# ATSAMB11G18A register map
Vendor: Atmel Corp; Series: SAMB11; File version: TODO
CPU: CM0 r0p0, little endian, no MPU, no FPU, 2 interrupt priority bits
Address unit: 32 bits
Registers are 32-bit, read-write, reset 0x0 unless marked. A register's access mark holds for its fields unless they carry their own. Offsets are from the block's base; [hi:lo] are bit positions; {n}, {i} and the like mark numbered series; 'fields as' and 'values as' point back to an identical list.

## LPMCU_MISC_REGS0 — LPMCU Misc Registers
Base 0x4000B000
0x00 LPMCU_CHIP_ID ro reset 0x2000B0 — The hard-coded ID for the chip.
  [23:0] REV_ID — Chip ID
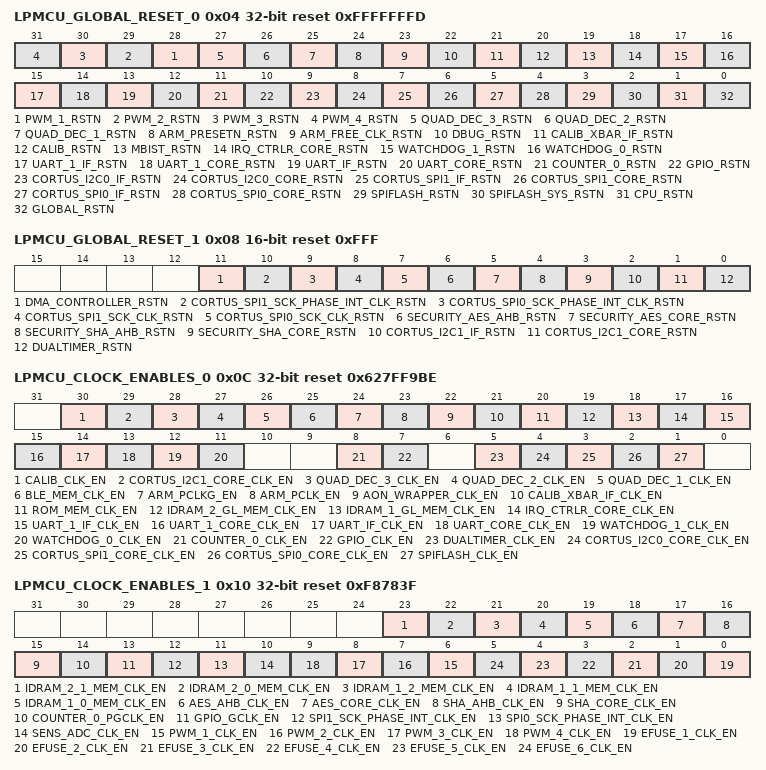
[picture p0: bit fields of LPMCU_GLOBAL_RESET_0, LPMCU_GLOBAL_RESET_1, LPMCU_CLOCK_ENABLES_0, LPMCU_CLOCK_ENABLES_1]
0x04 LPMCU_GLOBAL_RESET_0 reset 0xFFFFFFFD — All individual software controllable resets. 0: Reset the selected function. 1: Normal operation.
  [n+27] PWM_{n}_RSTN (n=1..4) — PWM{n-1} Reset
  [27] QUAD_DEC_3_RSTN — QUAD_DEC2 Reset
  [26] QUAD_DEC_2_RSTN — QUAD_DEC1 Reset
  [25] QUAD_DEC_1_RSTN — QUAD_DEC0 Reset
  [24] ARM_PRESETN_RSTN — ARM APB Reset
  [23] ARM_FREE_CLK_RSTN — Free Running ARM Clock Reset
  [22] DBUG_RSTN — LPMCU Debug Reset
  [21] CALIB_XBAR_IF_RSTN — Low Power Clock Calibration APB Reset
  [20] CALIB_RSTN — Low Power Clock Calibration Core Reset
  [19] MBIST_RSTN — MBIST Logic Reset
  [18] IRQ_CTRLR_CORE_RSTN — NVIC Reset
  [17] WATCHDOG_1_RSTN — WDT1 Reset
  [16] WATCHDOG_0_RSTN — WDT0 Reset
  [15] UART_1_IF_RSTN — UART1 Interface Reset
  [14] UART_1_CORE_RSTN — UART1 Core Reset
  [13] UART_IF_RSTN — UART0 Interface Reset
  [12] UART_CORE_RSTN — UART0 Core Reset
  [11] COUNTER_0_RSTN — TIMER0 Reset
  [10] GPIO_RSTN — GPIO Controller Reset
  [9] CORTUS_I2C0_IF_RSTN — I2C0 Interface Reset
  [8] CORTUS_I2C0_CORE_RSTN — I2C0 Core Reset
  [7] CORTUS_SPI1_IF_RSTN — SPI1 Interface Reset
  [6] CORTUS_SPI1_CORE_RSTN — SPI1 Core Reset
  [5] CORTUS_SPI0_IF_RSTN — SPI0 Interface Reset
  [4] CORTUS_SPI0_CORE_RSTN — SPI0 Core Reset
  [3] SPIFLASH_RSTN — SPI_FLASH0 Interface Reset
  [2] SPIFLASH_SYS_RSTN — SPI_FLASH0 Sys Reset
  [1] CPU_RSTN — LPMCU CPU Reset
  [0] GLOBAL_RSTN — LPMCU Global Reset (self setting)
0x08 LPMCU_GLOBAL_RESET_1 16-bit reset 0xFFF — All individual software controllable resets. 0: Reset the selected function. 1: Normal operation.
  [11] DMA_CONTROLLER_RSTN — PROV_DMA_CTRL0 Reset
  [10] CORTUS_SPI1_SCK_PHASE_INT_CLK_RSTN — SPI1 SCK Phase Clock Reset
  [9] CORTUS_SPI0_SCK_PHASE_INT_CLK_RSTN — SPI0 SCK Phase Clock Reset
  [8] CORTUS_SPI1_SCK_CLK_RSTN — SPI1 SCK Clock Reset
  [7] CORTUS_SPI0_SCK_CLK_RSTN — SPI0 SCK Clock Reset
  [6] SECURITY_AES_AHB_RSTN — Security AES AHB Interface Reset
  [5] SECURITY_AES_CORE_RSTN — Security AES Core Reset
  [4] SECURITY_SHA_AHB_RSTN — Security SHA AHB Interface Reset
  [3] SECURITY_SHA_CORE_RSTN — Security SHA Core Reset
  [2] CORTUS_I2C1_IF_RSTN — I2C1 Interface Reset
  [1] CORTUS_I2C1_CORE_RSTN — I2C1 Core Reset
  [0] DUALTIMER_RSTN — DUALTIMER0 Reset
0x0C LPMCU_CLOCK_ENABLES_0 reset 0x627FF9BE — All individual software controllable clock enables. Values are: 0: Disable clock. 1: Normal operation.
  [30] CALIB_CLK_EN — Low Power Clock Calibration Core Clock Enable
  [29] CORTUS_I2C1_CORE_CLK_EN — I2C1 Core Clock Enable
  [28] QUAD_DEC_3_CLK_EN — QUAD_DEC2 Clock Enable
  [27] QUAD_DEC_2_CLK_EN — QUAD_DEC1 Clock Enable
  [26] QUAD_DEC_1_CLK_EN — QUAD_DEC0 Clock Enable
  [25] BLE_MEM_CLK_EN — ARM BLE 8K Retention Memory Clock Enable
  [24] ARM_PCLKG_EN — ARM Gated PCLK Clock Enable (override)
  [23] ARM_PCLK_EN — ARM PCLK Clock Enable (override)
  [22] AON_WRAPPER_CLK_EN — AON Wrapper Clock Enable
  [21] CALIB_XBAR_IF_CLK_EN — Low Power Clock Calibration Interface Clock Enable
  [20] ROM_MEM_CLK_EN — ROM Clock Enable
  [19] IDRAM_2_GL_MEM_CLK_EN — IDRAM2 Glue Logic Clock Enable
  [18] IDRAM_1_GL_MEM_CLK_EN — IDRAM1 Glue Logic Clock Enable
  [17] IRQ_CTRLR_CORE_CLK_EN — NVIC Clock Enable
  [16] UART_1_IF_CLK_EN — UART1 Interface Clock Enable
  [15] UART_1_CORE_CLK_EN — UART1 Core Clock Enable
  [14] UART_IF_CLK_EN — UART0 Interface Clock Enable
  [13] UART_CORE_CLK_EN — UART0 Core Clock Enable
  [12] WATCHDOG_1_CLK_EN — WDT1 Clock Enable
  [11] WATCHDOG_0_CLK_EN — WDT0 Clock Enable
  [8] COUNTER_0_CLK_EN — TIMER0 Clock Enable
  [7] GPIO_CLK_EN — GPIO Controller Clock Enable
  [5] DUALTIMER_CLK_EN — DUALTIMER0 Clock Enable
  [4] CORTUS_I2C0_CORE_CLK_EN — I2C0 Core Clock Enable
  [3] CORTUS_SPI1_CORE_CLK_EN — SPI1 Core Clock Enable
  [2] CORTUS_SPI0_CORE_CLK_EN — SPI0 Core Clock Enable
  [1] SPIFLASH_CLK_EN — SPI_FLASH0 Clock Enable
0x10 LPMCU_CLOCK_ENABLES_1 reset 0xF8783F — All individual software controllable clock enables. Values are: 0: Disable clock. 1: Normal operation.
  [23] IDRAM_2_1_MEM_CLK_EN — IDRAM2_1 Memory Clock Enable
  [22] IDRAM_2_0_MEM_CLK_EN — IDRAM2_0 Memory Clock Enable
  [21] IDRAM_1_2_MEM_CLK_EN — IDRAM1_2 Memory Clock Enable
  [20] IDRAM_1_1_MEM_CLK_EN — IDRAM1_1 Memory Clock Enable
  [19] IDRAM_1_0_MEM_CLK_EN — IDRAM1_0 Memory Clock Enable
  [18] AES_AHB_CLK_EN — AES AHB Clock Enable
  [17] AES_CORE_CLK_EN — AES Core Clock Enable
  [16] SHA_AHB_CLK_EN — SHA AHB Clock Enable
  [15] SHA_CORE_CLK_EN — SHA Core Clock Enable
  [14] COUNTER_0_PGCLK_EN — TIMER0 Gated APB Clock
  [13] GPIO_GCLK_EN — GPIO Controller Clock Enable
  [12] SPI1_SCK_PHASE_INT_CLK_EN — SPI1 SCK Phase Internal Clock Enable
  [11] SPI0_SCK_PHASE_INT_CLK_EN — SPI0 SCK Phase Internal Clock Enable
  [10] SENS_ADC_CLK_EN — PMU Sensor ADC Clock Enable
  [n+5] PWM_{n}_CLK_EN (n=1..4) — PWM{n-1} Clock Enable
  [n-1] EFUSE_{n}_CLK_EN (n=1..6) — EFUSE{n-1} Clock Enable
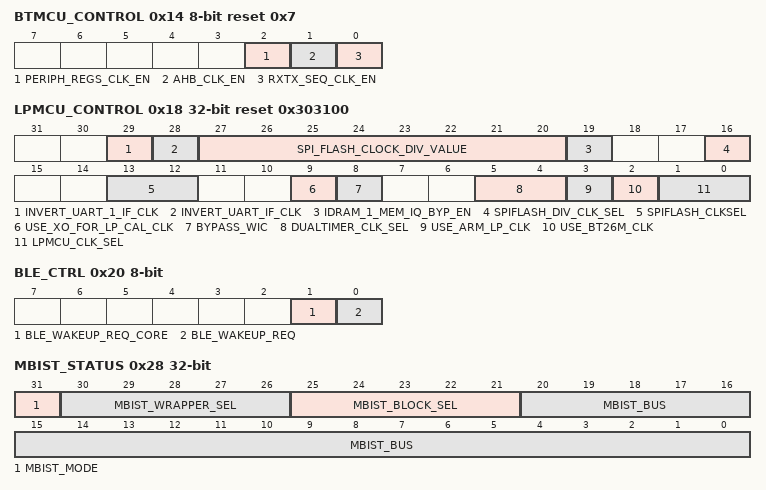
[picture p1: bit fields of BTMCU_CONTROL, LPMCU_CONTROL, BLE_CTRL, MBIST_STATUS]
0x14 BTMCU_CONTROL 8-bit reset 0x7 — Miscellaneous BLE control
  [2] PERIPH_REGS_CLK_EN — BLE Periph Regs Clock Enable
  [1] AHB_CLK_EN — BLE HAB Clock Enable
  [0] RXTX_SEQ_CLK_EN — BLE RXTX Sequencer Clock Enable
0x18 LPMCU_CONTROL reset 0x303100 — Miscellaneous LPMCU control
  [29] INVERT_UART_1_IF_CLK — Inverts UART1 interface clock
  [28] INVERT_UART_IF_CLK — Inverts UART0 interface clock
  [27:20] SPI_FLASH_CLOCK_DIV_VALUE — Integer divider value. 26mhz clock will be divided by this register value
  [19] IDRAM_1_MEM_IQ_BYP_EN — Mux Control to select between FECE and standard IDRAM memory. Default to IDRAM ARM Memory
  [16] SPIFLASH_DIV_CLK_SEL — Use Generated Divided Clock for SPI_FLASH0
  [13:12] SPIFLASH_CLKSEL — SPI_FLASH0 Clock Frequency Select
    0=3.25MHz; 1=6.5MHz; 2=13MHz; 3=26MHz
  [9] USE_XO_FOR_LP_CAL_CLK — Use the XO for Low Power Clock Calibration
  [8] BYPASS_WIC — Bypass Wakeup Interrupt Controller
  [5:4] DUALTIMER_CLK_SEL — DUALTIMER0 Clock Frequency Select
    0=26MHz; 1=13MHz; 2=6.5MHz; 3=3.25MHz
  [3] USE_ARM_LP_CLK — Use either LP 2MHz clock or XO as ARM clock
  [2] USE_BT26M_CLK — Use XO as ARM clock (must also set use_arm_lp_clk)
  [1:0] LPMCU_CLK_SEL — LPMCU Clock Frequency Selection
    0=26MHz; 1=13MHz; 2=6.5MHz; 3=3.25MHz
0x1C LPMCU_MBIST 8-bit — MBIST designation
  [0] MBIST_MODE — Puts the chip in MBIST mode
0x20 BLE_CTRL 8-bit — BLE Control
  [1] BLE_WAKEUP_REQ_CORE — BLE Wakeup Request (to BLE Core)
  [0] BLE_WAKEUP_REQ — BLE Wakeup Request (to BLE Sleep Timer)
0x24 MBIST_CONTROL (reset mask 0x7FFFF)
0x28 MBIST_STATUS ro
  [31] MBIST_MODE — Observation of mbist_mode signal
  [30:26] MBIST_WRAPPER_SEL — Observation of wrapper field of MBIST control
  [25:21] MBIST_BLOCK_SEL — Observation of block field of MBIST control
  [20:0] MBIST_BUS — Observation of MBIST results
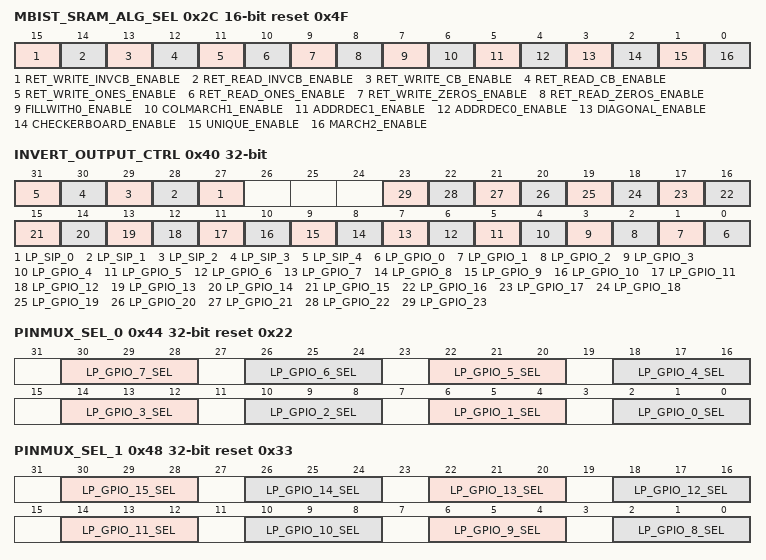
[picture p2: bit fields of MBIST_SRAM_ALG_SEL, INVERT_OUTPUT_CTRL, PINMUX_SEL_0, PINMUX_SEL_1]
0x2C MBIST_SRAM_ALG_SEL 16-bit reset 0x4F — Enables MBIST algorithms
  [15] RET_WRITE_INVCB_ENABLE — Enables the ret write inv checkerboard algorithm
  [14] RET_READ_INVCB_ENABLE — Enables the ret read inv checkerboard algorithm
  [13] RET_WRITE_CB_ENABLE — Enables the ret write checkerboard algorithm
  [12] RET_READ_CB_ENABLE — Enables the ret read checkerboard algorithm
  [11] RET_WRITE_ONES_ENABLE — Enables the ret write ones algorithm
  [10] RET_READ_ONES_ENABLE — Enables the ret read ones algorithm
  [9] RET_WRITE_ZEROS_ENABLE — Enables the ret write zeros algorithm
  [8] RET_READ_ZEROS_ENABLE — Enables the ret read zeros algorithm
  [7] FILLWITH0_ENABLE — Enables the fillwith0 algorithm
  [6] COLMARCH1_ENABLE — Enables the col_march1 algorithm
  [5] ADDRDEC1_ENABLE — Enables the address decoder bg1 algorithm
  [4] ADDRDEC0_ENABLE — Enables the address decoder bg0 algorithm
  [3] DIAGONAL_ENABLE — Enables the diagonal algorithm
  [2] CHECKERBOARD_ENABLE — Enables the checkerboard algorithm
  [1] UNIQUE_ENABLE — Enables the unique address algorithm
  [0] MARCH2_ENABLE — Enables the march2 algorithm
0x30 MBIST_BG — MBIST Background for MARCH2 algorithm (bits 31:0)
0x38 TEST_BUS_CONTROL 8-bit — Controls all of the test bus functionality
  [0] TEST_ENABLE_ARM — Selects periph test bus
0x3C WP3_MISR_DATAOUT ro — ROM MBIST Signature
0x40 INVERT_OUTPUT_CTRL — Invert Output Control
  [n+27] LP_SIP_{n} (n=0..4) — Invert the output for lp_sip_{n}
  [n] LP_GPIO_{n} (n=0..23) — Invert the output for lp_gpio_{n}
0x44 PINMUX_SEL_0 reset 0x22 — Pinmux select for LP_GPIO_0, LP_GPIO_1, LP_GPIO_2, LP_GPIO_3, LP_GPIO_4, LP_GPIO_5, LP_GPIO_6, LP_GPIO_7
  [30:28] LP_GPIO_7_SEL — Pinmux select for LP_GPIO_7
    0=GPIO (MUX function 0); 1=MEGAMUX (MUX function 1); 2=UART1_TXD (MUX function 2); 5=SPI0_MOSI (MUX function 5); 6=SPI_FLASH0_TXD (MUX function 6); 7=TEST_OUT_7 (MUX function 7)
  [26:24] LP_GPIO_6_SEL — Pinmux select for LP_GPIO_6
    0=GPIO (MUX function 0); 1=MEGAMUX (MUX function 1); 2=UART1_RXD (MUX function 2); 5=SPI0_SCK (MUX function 5); 6=SPI_FLASH0_SCK (MUX function 6); 7=TEST_OUT_6 (MUX function 7)
  [22:20] LP_GPIO_5_SEL — Pinmux select for LP_GPIO_5
    0=GPIO (MUX function 0); 1=MEGAMUX (MUX function 1); 2=UART0_RTS (MUX function 2); 4=SPI1_MISO (MUX function 4); 5=SPI0_MISO (MUX function 5); 6=SPI_FLASH0_RXD (MUX function 6); 7=TEST_OUT_5 (MUX function 7)
  [18:16] LP_GPIO_4_SEL — Pinmux select for LP_GPIO_4
    0=GPIO (MUX function 0); 1=MEGAMUX (MUX function 1); 2=UART0_CTS (MUX function 2); 4=SPI1_SSN (MUX function 4); 5=SPI0_SSN (MUX function 5); 6=SPI_FLASH0_SSN (MUX function 6); 7=TEST_OUT_4 (MUX function 7)
  [14:12] LP_GPIO_3_SEL — Pinmux select for LP_GPIO_3
    0=GPIO (MUX function 0); 1=MEGAMUX (MUX function 1); 2=UART0_TXD (MUX function 2); 4=SPI1_MOSI (MUX function 4); 5=SPI0_MOSI (MUX function 5); 6=SPI_FLASH0_TXD (MUX function 6); 7=TEST_OUT_3 (MUX function 7)
  [10:8] LP_GPIO_2_SEL — Pinmux select for LP_GPIO_2
    0=GPIO (MUX function 0); 1=MEGAMUX (MUX function 1); 2=UART0_RXD (MUX function 2); 4=SPI1_SCK (MUX function 4); 5=SPI0_SCK (MUX function 5); 6=SPI_FLASH0_SCK (MUX function 6); 7=TEST_OUT_2 (MUX function 7)
  [6:4] LP_GPIO_1_SEL — Pinmux select for LP_GPIO_1
    0=GPIO (MUX function 0); 1=MEGAMUX (MUX function 1); 2=SWD_IO (MUX function 2); 7=TEST_OUT_1 (MUX function 7)
  [2:0] LP_GPIO_0_SEL — Pinmux select for LP_GPIO_0
    0=GPIO (MUX function 0); 1=MEGAMUX (MUX function 1); 2=SWD_CLK (MUX function 2); 7=TEST_OUT_0 (MUX function 7)
0x48 PINMUX_SEL_1 reset 0x33 — Pinmux select for LP_GPIO_8, LP_GPIO_9, LP_GPIO_10, LP_GPIO_11, LP_GPIO_12, LP_GPIO_13, LP_GPIO_14, LP_GPIO_15
  [30:28] LP_GPIO_15_SEL — Pinmux select for LP_GPIO_15
    0=GPIO (MUX function 0); 1=MEGAMUX (MUX function 1); 2=UART1_RTS (MUX function 2); 4=I2C1_SCL (MUX function 4); 7=TEST_OUT_15 (MUX function 7)
  [26:24] LP_GPIO_14_SEL — Pinmux select for LP_GPIO_14
    0=GPIO (MUX function 0); 1=MEGAMUX (MUX function 1); 2=UART1_CTS (MUX function 2); 4=I2C1_SDA (MUX function 4); 7=TEST_OUT_14 (MUX function 7)
  [22:20] LP_GPIO_13_SEL — Pinmux select for LP_GPIO_13
    0=GPIO (MUX function 0); 1=MEGAMUX (MUX function 1); 2=SPI0_MISO (MUX function 2); 6=SPI_FLASH0_RXD (MUX function 6); 7=TEST_OUT_13 (MUX function 7)
  [18:16] LP_GPIO_12_SEL — Pinmux select for LP_GPIO_12
    0=GPIO (MUX function 0); 1=MEGAMUX (MUX function 1); 2=SPI0_SSN (MUX function 2); 6=SPI_FLASH0_SSN (MUX function 6); 7=TEST_OUT_12 (MUX function 7)
  [14:12] LP_GPIO_11_SEL — Pinmux select for LP_GPIO_11
    0=GPIO (MUX function 0); 1=MEGAMUX (MUX function 1); 2=SPI0_MOSI (MUX function 2); 6=SPI_FLASH0_TXD (MUX function 6); 7=TEST_OUT_11 (MUX function 7)
  [10:8] LP_GPIO_10_SEL — Pinmux select for LP_GPIO_10
    0=GPIO (MUX function 0); 1=MEGAMUX (MUX function 1); 2=SPI0_SCK (MUX function 2); 6=SPI_FLASH0_SCK (MUX function 6); 7=TEST_OUT_10 (MUX function 7)
  [6:4] LP_GPIO_9_SEL — Pinmux select for LP_GPIO_9
    0=GPIO (MUX function 0); 1=MEGAMUX (MUX function 1); 2=I2C0_SCL (MUX function 2); 5=SPI0_MISO (MUX function 5); 6=SPI_FLASH0_RXD (MUX function 6); 7=TEST_OUT_9 (MUX function 7)
  [2:0] LP_GPIO_8_SEL — Pinmux select for LP_GPIO_8
    0=GPIO (MUX function 0); 1=MEGAMUX (MUX function 1); 2=I2C0_SDA (MUX function 2); 5=SPI0_SSN (MUX function 5); 6=SPI_FLASH0_SSN (MUX function 6); 7=TEST_OUT_8 (MUX function 7)
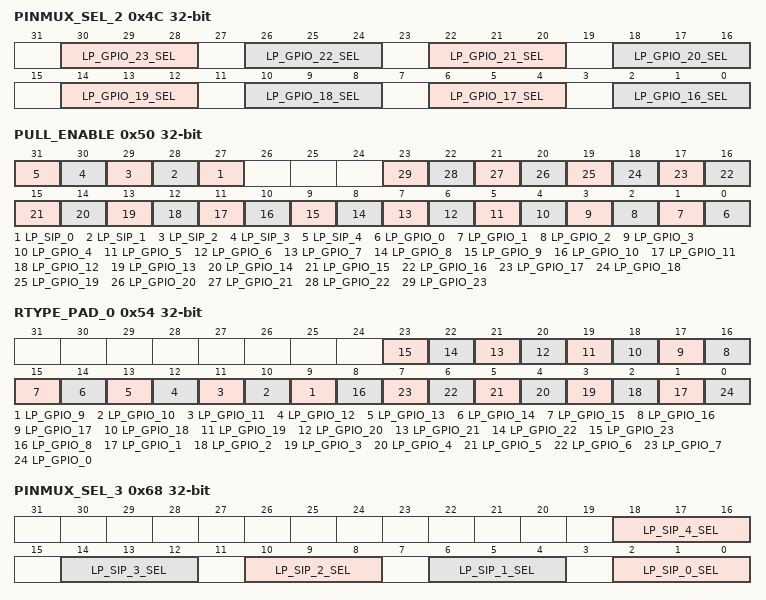
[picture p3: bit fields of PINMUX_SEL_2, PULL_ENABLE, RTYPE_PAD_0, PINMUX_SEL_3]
0x4C PINMUX_SEL_2 — Pinmux select for LP_GPIO_16, LP_GPIO_17, LP_GPIO_18, LP_GPIO_19, LP_GPIO_20, LP_GPIO_21, LP_GPIO_22, LP_GPIO_23
  [30:28] LP_GPIO_23_SEL — Pinmux select for LP_GPIO_23
    0=GPIO (MUX function 0); 1=MEGAMUX (MUX function 1)
  [26:24] LP_GPIO_22_SEL — Pinmux select for LP_GPIO_22
    0=GPIO (MUX function 0); 1=MEGAMUX (MUX function 1)
  [22:20] LP_GPIO_21_SEL — Pinmux select for LP_GPIO_21
    0=GPIO (MUX function 0); 1=MEGAMUX (MUX function 1)
  [18:16] LP_GPIO_20_SEL — Pinmux select for LP_GPIO_20
    0=GPIO (MUX function 0); 1=MEGAMUX (MUX function 1); 7=TEST_OUT_20 (MUX function 7)
  [14:12] LP_GPIO_19_SEL — Pinmux select for LP_GPIO_19
    0=GPIO (MUX function 0); 1=MEGAMUX (MUX function 1); 2=SPI_FLASH0_RXD (MUX function 2); 4=SPI1_MOSI (MUX function 4); 5=SPI0_MISO (MUX function 5); 7=TEST_OUT_19 (MUX function 7)
  [10:8] LP_GPIO_18_SEL — Pinmux select for LP_GPIO_18
    0=GPIO (MUX function 0); 1=MEGAMUX (MUX function 1); 2=SPI_FLASH0_SSN (MUX function 2); 4=SPI1_MISO (MUX function 4); 5=SPI0_SSN (MUX function 5); 6=SPI_FLASH0_RXD (MUX function 6); 7=TEST_OUT_18 (MUX function 7)
  [6:4] LP_GPIO_17_SEL — Pinmux select for LP_GPIO_17
    0=GPIO (MUX function 0); 1=MEGAMUX (MUX function 1); 2=SPI_FLASH0_TXD (MUX function 2); 4=SPI1_SCK (MUX function 4); 5=SPI0_MOSI (MUX function 5); 7=TEST_OUT_17 (MUX function 7)
  [2:0] LP_GPIO_16_SEL — Pinmux select for LP_GPIO_16
    0=GPIO (MUX function 0); 1=MEGAMUX (MUX function 1); 2=SPI_FLASH0_SCK (MUX function 2); 4=SPI1_SSN (MUX function 4); 5=SPI0_SCK (MUX function 5); 6=SPI_FLASH0_SSN (MUX function 6); 7=TEST_OUT_16 (MUX function 7)
0x50 PULL_ENABLE — Active Low Pull Enables for LPMCU Pads
  [n+27] LP_SIP_{n} (n=0..4) — Pull Enable for LP_SIP_{n}
  [n] LP_GPIO_{n} (n=0..23) — Pull Enable for LP_GPIO_{n}
0x54 RTYPE_PAD_0 — Controls the RTYPE (Pull Level) pad value for LPMCU Pads (0 = Pull Up)
  [n] LP_GPIO_{n} (n=9..23) — Controls RTYPE (Pull Level) value LP_GPIO_{n}
  [8] LP_GPIO_8 — Controls RTYPE (Pull Level) value for LP_GPIO_8
  [n] LP_GPIO_{n} (n=1..7) — Controls RTYPE (Pull Level) value LP_GPIO_{n}
  [0] LP_GPIO_0 — Controls RTYPE (Pull Level) value for LP_GPIO_0
0x68 PINMUX_SEL_3 — Pinmux select for LP_SIP_0, LP_SIP_1, LP_SIP_2, LP_SIP_3, LP_SIP_4
  [18:16] LP_SIP_4_SEL — Pinmux select for LP_SIP_4
    0=SPI_FLASH0_WP (MUX function 0)
  [14:12] LP_SIP_3_SEL — Pinmux select for LP_SIP_3
    4=SPI_FLASH0_RXD (MUX function 4)
  [10:8] LP_SIP_2_SEL — Pinmux select for LP_SIP_2
    2=SPI_FLASH0_SSN (MUX function 2)
  [6:4] LP_SIP_1_SEL — Pinmux select for LP_SIP_1
    3=SPI_FLASH0_TXD (MUX function 3)
  [2:0] LP_SIP_0_SEL — Pinmux select for LP_SIP_0
    1=SPI_FLASH0_SCK (MUX function 1)
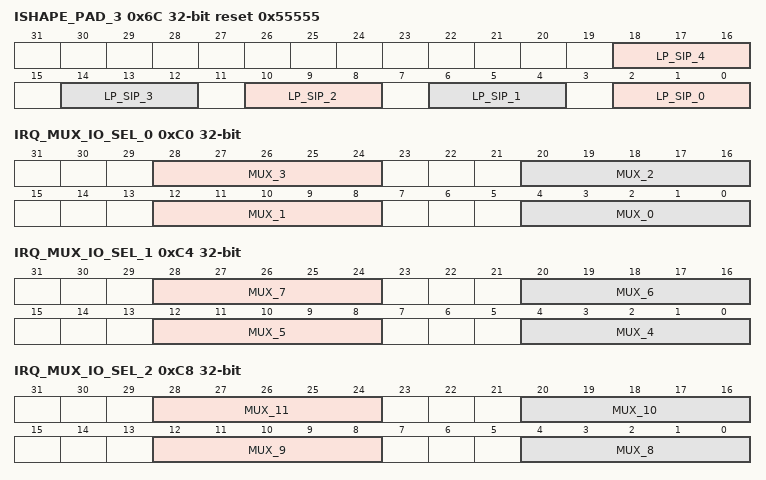
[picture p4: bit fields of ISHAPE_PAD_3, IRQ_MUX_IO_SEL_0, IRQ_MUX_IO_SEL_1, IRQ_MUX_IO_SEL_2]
0x6C ISHAPE_PAD_3 reset 0x55555 — Controls the ISHAPE pad value for LPMCU SIP Pads
  [4n+2:4n] LP_SIP_{n} (n=0..4) — Controls ISHAPE value LP_SIP_{n}
0x80 PINMUX_SEL_4 8-bit — Pinmux select for LP_GPIO_24
  [2:0] LP_GPIO_24_SEL
    0=GPIO (MUX function 0); 1=MEGAMUX (MUX function 1)
0x90 LPMCU_CONTROL_2 8-bit — Misc control for the LPMCU
  [7:0] SPI_FLASH_CLOCK_FRAC_VALUE — SPI_FLASH0 Fractional Divider Value
0xA0 SPIFLASH_VDDIO_CTRL 8-bit reset 0x1 — Control for VDDIO of SPI FLASH
  [0] ENABLE — Enables power for the stacked (internal) SPI FLASH
0xA4 SPIFLASH_BYPASS 8-bit
  [0] ENABLE — Enables Bypass of SPI Flash Controller
0xC0 IRQ_MUX_IO_SEL_0 — Arm Cortex IRQ Mux Selection (Refer to Interrupts Spreadsheet)
  [28:24] MUX_3 — IRQ_3 Source Selection
    0=UART1 TX; 1=UART0 RX; 2=UART0 TX; 3=UART1 RX; 4=UART1 TX; 5=SPI0 RX; 6=SPI0 TX; 7=SPI1 RX; 8=SPI1 TX; 9=I2C0 RX; 10=I2C0 TX; 11=I2C1 RX; 12=I2C1 TX; 13=WDT0; 14=WDT1; 15=DUALTIMER0; 16=PROV_DMA_CTRL0; 17=SECURITY; 18=EFUSE_OUT_OF_RESET; 19=QUAD_DEC0_1_2; 20=BLE_FRONTEND; 21=PROG_AHB_TRIG_TIMEOUT; 22=SXPLL_NEED_RESET; 23=LP_CLK_CAL_DONE; 24=BROWNOUT_DETECTED
  [20:16] MUX_2 — IRQ_2 Source Selection
    0=UART1 RX; 1=UART0 RX; 2=UART0 TX; 3=UART1 RX; 4=UART1 TX; 5=SPI0 RX; 6=SPI0 TX; 7=SPI1 RX; 8=SPI1 TX; 9=I2C0 RX; 10=I2C0 TX; 11=I2C1 RX; 12=I2C1 TX; 13=WDT0; 14=WDT1; 15=DUALTIMER0; 16=PROV_DMA_CTRL0; 17=SECURITY; 18=EFUSE_OUT_OF_RESET; 19=QUAD_DEC0_1_2; 20=BLE_FRONTEND; 21=PROG_AHB_TRIG_TIMEOUT; 22=SXPLL_NEED_RESET; 23=LP_CLK_CAL_DONE; 24=BROWNOUT_DETECTED
  [12:8] MUX_1 — IRQ_1 Source Selection
    0=UART0 TX; 1=UART0 RX; 2=UART0 TX; 3=UART1 RX; 4=UART1 TX; 5=SPI0 RX; 6=SPI0 TX; 7=SPI1 RX; 8=SPI1 TX; 9=I2C0 RX; 10=I2C0 TX; 11=I2C1 RX; 12=I2C1 TX; 13=WDT0; 14=WDT1; 15=DUALTIMER0; 16=PROV_DMA_CTRL0; 17=SECURITY; 18=EFUSE_OUT_OF_RESET; 19=QUAD_DEC0_1_2; 20=BLE_FRONTEND; 21=PROG_AHB_TRIG_TIMEOUT; 22=SXPLL_NEED_RESET; 23=LP_CLK_CAL_DONE; 24=BROWNOUT_DETECTED
  [4:0] MUX_0 — IRQ_0 Source Selection
    0=UART0 RX; 1=UART0 RX; 2=UART0 TX; 3=UART1 RX; 4=UART1 TX; 5=SPI0 RX; 6=SPI0 TX; 7=SPI1 RX; 8=SPI1 TX; 9=I2C0 RX; 10=I2C0 TX; 11=I2C1 RX; 12=I2C1 TX; 13=WDT0; 14=WDT1; 15=DUALTIMER0; 16=PROV_DMA_CTRL0; 17=SECURITY; 18=EFUSE_OUT_OF_RESET; 19=QUAD_DEC0_1_2; 20=BLE_FRONTEND; 21=PROG_AHB_TRIG_TIMEOUT; 22=SXPLL_NEED_RESET; 23=LP_CLK_CAL_DONE; 24=BROWNOUT_DETECTED
0xC4 IRQ_MUX_IO_SEL_1 — Arm Cortex IRQ Mux Selection (Refer to Interrupts Spreadsheet)
  [28:24] MUX_7 — IRQ_7 Source Selection
    0=SPI1 TX; 1=UART0 RX; 2=UART0 TX; 3=UART1 RX; 4=UART1 TX; 5=SPI0 RX; 6=SPI0 TX; 7=SPI1 RX; 8=SPI1 TX; 9=I2C0 RX; 10=I2C0 TX; 11=I2C1 RX; 12=I2C1 TX; 13=WDT0; 14=WDT1; 15=DUALTIMER0; 16=PROV_DMA_CTRL0; 17=SECURITY; 18=EFUSE_OUT_OF_RESET; 19=QUAD_DEC0_1_2; 20=BLE_FRONTEND; 21=PROG_AHB_TRIG_TIMEOUT; 22=SXPLL_NEED_RESET; 23=LP_CLK_CAL_DONE; 24=BROWNOUT_DETECTED
  [20:16] MUX_6 — IRQ_6 Source Selection
    0=SPI1 RX; 1=UART0 RX; 2=UART0 TX; 3=UART1 RX; 4=UART1 TX; 5=SPI0 RX; 6=SPI0 TX; 7=SPI1 RX; 8=SPI1 TX; 9=I2C0 RX; 10=I2C0 TX; 11=I2C1 RX; 12=I2C1 TX; 13=WDT0; 14=WDT1; 15=DUALTIMER0; 16=PROV_DMA_CTRL0; 17=SECURITY; 18=EFUSE_OUT_OF_RESET; 19=QUAD_DEC0_1_2; 20=BLE_FRONTEND; 21=PROG_AHB_TRIG_TIMEOUT; 22=SXPLL_NEED_RESET; 23=LP_CLK_CAL_DONE; 24=BROWNOUT_DETECTED
  [12:8] MUX_5 — IRQ_5 Source Selection
    0=SPI0 TX; 1=UART0 RX; 2=UART0 TX; 3=UART1 RX; 4=UART1 TX; 5=SPI0 RX; 6=SPI0 TX; 7=SPI1 RX; 8=SPI1 TX; 9=I2C0 RX; 10=I2C0 TX; 11=I2C1 RX; 12=I2C1 TX; 13=WDT0; 14=WDT1; 15=DUALTIMER0; 16=PROV_DMA_CTRL0; 17=SECURITY; 18=EFUSE_OUT_OF_RESET; 19=QUAD_DEC0_1_2; 20=BLE_FRONTEND; 21=PROG_AHB_TRIG_TIMEOUT; 22=SXPLL_NEED_RESET; 23=LP_CLK_CAL_DONE; 24=BROWNOUT_DETECTED
  [4:0] MUX_4 — IRQ_4 Source Selection
    0=SPI0 RX; 1=UART0 RX; 2=UART0 TX; 3=UART1 RX; 4=UART1 TX; 5=SPI0 RX; 6=SPI0 TX; 7=SPI1 RX; 8=SPI1 TX; 9=I2C0 RX; 10=I2C0 TX; 11=I2C1 RX; 12=I2C1 TX; 13=WDT0; 14=WDT1; 15=DUALTIMER0; 16=PROV_DMA_CTRL0; 17=SECURITY; 18=EFUSE_OUT_OF_RESET; 19=QUAD_DEC0_1_2; 20=BLE_FRONTEND; 21=PROG_AHB_TRIG_TIMEOUT; 22=SXPLL_NEED_RESET; 23=LP_CLK_CAL_DONE; 24=BROWNOUT_DETECTED
0xC8 IRQ_MUX_IO_SEL_2 — Arm Cortex IRQ Mux Selection (Refer to Interrupts Spreadsheet)
  [28:24] MUX_11 — IRQ_11 Source Selection
    0=I2C1 TX; 1=UART0 RX; 2=UART0 TX; 3=UART1 RX; 4=UART1 TX; 5=SPI0 RX; 6=SPI0 TX; 7=SPI1 RX; 8=SPI1 TX; 9=I2C0 RX; 10=I2C0 TX; 11=I2C1 RX; 12=I2C1 TX; 13=WDT0; 14=WDT1; 15=DUALTIMER0; 16=PROV_DMA_CTRL0; 17=SECURITY; 18=EFUSE_OUT_OF_RESET; 19=QUAD_DEC0_1_2; 20=BLE_FRONTEND; 21=PROG_AHB_TRIG_TIMEOUT; 22=SXPLL_NEED_RESET; 23=LP_CLK_CAL_DONE; 24=BROWNOUT_DETECTED
  [20:16] MUX_10 — IRQ_10 Source Selection
    0=I2C1 RX; 1=UART0 RX; 2=UART0 TX; 3=UART1 RX; 4=UART1 TX; 5=SPI0 RX; 6=SPI0 TX; 7=SPI1 RX; 8=SPI1 TX; 9=I2C0 RX; 10=I2C0 TX; 11=I2C1 RX; 12=I2C1 TX; 13=WDT0; 14=WDT1; 15=DUALTIMER0; 16=PROV_DMA_CTRL0; 17=SECURITY; 18=EFUSE_OUT_OF_RESET; 19=QUAD_DEC0_1_2; 20=BLE_FRONTEND; 21=PROG_AHB_TRIG_TIMEOUT; 22=SXPLL_NEED_RESET; 23=LP_CLK_CAL_DONE; 24=BROWNOUT_DETECTED
  [12:8] MUX_9 — IRQ_9 Source Selection
    0=I2C0 TX; 1=UART0 RX; 2=UART0 TX; 3=UART1 RX; 4=UART1 TX; 5=SPI0 RX; 6=SPI0 TX; 7=SPI1 RX; 8=SPI1 TX; 9=I2C0 RX; 10=I2C0 TX; 11=I2C1 RX; 12=I2C1 TX; 13=WDT0; 14=WDT1; 15=DUALTIMER0; 16=PROV_DMA_CTRL0; 17=SECURITY; 18=EFUSE_OUT_OF_RESET; 19=QUAD_DEC0_1_2; 20=BLE_FRONTEND; 21=PROG_AHB_TRIG_TIMEOUT; 22=SXPLL_NEED_RESET; 23=LP_CLK_CAL_DONE; 24=BROWNOUT_DETECTED
  [4:0] MUX_8 — IRQ_8 Source Selection
    0=I2C0 RX; 1=UART0 RX; 2=UART0 TX; 3=UART1 RX; 4=UART1 TX; 5=SPI0 RX; 6=SPI0 TX; 7=SPI1 RX; 8=SPI1 TX; 9=I2C0 RX; 10=I2C0 TX; 11=I2C1 RX; 12=I2C1 TX; 13=WDT0; 14=WDT1; 15=DUALTIMER0; 16=PROV_DMA_CTRL0; 17=SECURITY; 18=EFUSE_OUT_OF_RESET; 19=QUAD_DEC0_1_2; 20=BLE_FRONTEND; 21=PROG_AHB_TRIG_TIMEOUT; 22=SXPLL_NEED_RESET; 23=LP_CLK_CAL_DONE; 24=BROWNOUT_DETECTED
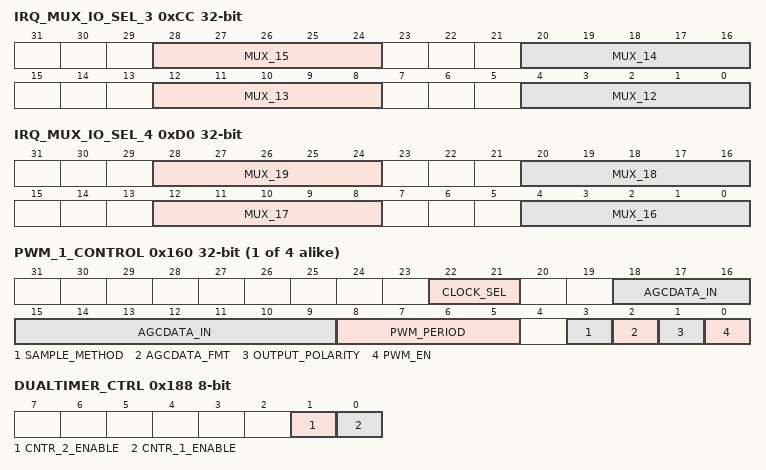
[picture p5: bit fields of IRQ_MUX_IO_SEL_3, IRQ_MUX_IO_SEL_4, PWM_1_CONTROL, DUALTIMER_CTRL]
0xCC IRQ_MUX_IO_SEL_3 — Arm Cortex IRQ Mux Selection (Refer to Interrupts Spreadsheet)
  [28:24] MUX_15 — IRQ_15 Source Selection
    0=PROV_DMA_CTRL0; 1=UART0 RX; 2=UART0 TX; 3=UART1 RX; 4=UART1 TX; 5=SPI0 RX; 6=SPI0 TX; 7=SPI1 RX; 8=SPI1 TX; 9=I2C0 RX; 10=I2C0 TX; 11=I2C1 RX; 12=I2C1 TX; 13=WDT0; 14=WDT1; 15=DUALTIMER0; 16=PROV_DMA_CTRL0; 17=SECURITY; 18=EFUSE_OUT_OF_RESET; 19=QUAD_DEC0_1_2; 20=BLE_FRONTEND; 21=PROG_AHB_TRIG_TIMEOUT; 22=SXPLL_NEED_RESET; 23=LP_CLK_CAL_DONE; 24=BROWNOUT_DETECTED
  [20:16] MUX_14 — IRQ_14 Source Selection
    0=DUALTIMER0; 1=UART0 RX; 2=UART0 TX; 3=UART1 RX; 4=UART1 TX; 5=SPI0 RX; 6=SPI0 TX; 7=SPI1 RX; 8=SPI1 TX; 9=I2C0 RX; 10=I2C0 TX; 11=I2C1 RX; 12=I2C1 TX; 13=WDT0; 14=WDT1; 15=DUALTIMER0; 16=PROV_DMA_CTRL0; 17=SECURITY; 18=EFUSE_OUT_OF_RESET; 19=QUAD_DEC0_1_2; 20=BLE_FRONTEND; 21=PROG_AHB_TRIG_TIMEOUT; 22=SXPLL_NEED_RESET; 23=LP_CLK_CAL_DONE; 24=BROWNOUT_DETECTED
  [12:8] MUX_13 — IRQ_13 Source Selection
    0=WDT1; 1=UART0 RX; 2=UART0 TX; 3=UART1 RX; 4=UART1 TX; 5=SPI0 RX; 6=SPI0 TX; 7=SPI1 RX; 8=SPI1 TX; 9=I2C0 RX; 10=I2C0 TX; 11=I2C1 RX; 12=I2C1 TX; 13=WDT0; 14=WDT1; 15=DUALTIMER0; 16=PROV_DMA_CTRL0; 17=SECURITY; 18=EFUSE_OUT_OF_RESET; 19=QUAD_DEC0_1_2; 20=BLE_FRONTEND; 21=PROG_AHB_TRIG_TIMEOUT; 22=SXPLL_NEED_RESET; 23=LP_CLK_CAL_DONE; 24=BROWNOUT_DETECTED
  [4:0] MUX_12 — IRQ_12 Source Selection
    0=WDT0; 1=UART0 RX; 2=UART0 TX; 3=UART1 RX; 4=UART1 TX; 5=SPI0 RX; 6=SPI0 TX; 7=SPI1 RX; 8=SPI1 TX; 9=I2C0 RX; 10=I2C0 TX; 11=I2C1 RX; 12=I2C1 TX; 13=WDT0; 14=WDT1; 15=DUALTIMER0; 16=PROV_DMA_CTRL0; 17=SECURITY; 18=EFUSE_OUT_OF_RESET; 19=QUAD_DEC0_1_2; 20=BLE_FRONTEND; 21=PROG_AHB_TRIG_TIMEOUT; 22=SXPLL_NEED_RESET; 23=LP_CLK_CAL_DONE; 24=BROWNOUT_DETECTED
0xD0 IRQ_MUX_IO_SEL_4 — Arm Cortex IRQ Mux Selection (Refer to Interrupts Spreadsheet)
  [28:24] MUX_19 — IRQ_19 Source Selection
    0=LP_CLK_CAL_DONE; 1=UART0 RX; 2=UART0 TX; 3=UART1 RX; 4=UART1 TX; 5=SPI0 RX; 6=SPI0 TX; 7=SPI1 RX; 8=SPI1 TX; 9=I2C0 RX; 10=I2C0 TX; 11=I2C1 RX; 12=I2C1 TX; 13=WDT0; 14=WDT1; 15=DUALTIMER0; 16=PROV_DMA_CTRL0; 17=SECURITY; 18=EFUSE_OUT_OF_RESET; 19=QUAD_DEC0_1_2; 20=BLE_FRONTEND; 21=PROG_AHB_TRIG_TIMEOUT; 22=SXPLL_NEED_RESET; 23=LP_CLK_CAL_DONE; 24=BROWNOUT_DETECTED
  [20:16] MUX_18 — IRQ_18 Source Selection
    0=SXPLL_NEED_RESET; 1=UART0 RX; 2=UART0 TX; 3=UART1 RX; 4=UART1 TX; 5=SPI0 RX; 6=SPI0 TX; 7=SPI1 RX; 8=SPI1 TX; 9=I2C0 RX; 10=I2C0 TX; 11=I2C1 RX; 12=I2C1 TX; 13=WDT0; 14=WDT1; 15=DUALTIMER0; 16=PROV_DMA_CTRL0; 17=SECURITY; 18=EFUSE_OUT_OF_RESET; 19=QUAD_DEC0_1_2; 20=BLE_FRONTEND; 21=PROG_AHB_TRIG_TIMEOUT; 22=SXPLL_NEED_RESET; 23=LP_CLK_CAL_DONE; 24=BROWNOUT_DETECTED
  [12:8] MUX_17 — IRQ_17 Source Selection
    0=EFUSE_OUT_OF_RESET; 1=UART0 RX; 2=UART0 TX; 3=UART1 RX; 4=UART1 TX; 5=SPI0 RX; 6=SPI0 TX; 7=SPI1 RX; 8=SPI1 TX; 9=I2C0 RX; 10=I2C0 TX; 11=I2C1 RX; 12=I2C1 TX; 13=WDT0; 14=WDT1; 15=DUALTIMER0; 16=PROV_DMA_CTRL0; 17=SECURITY; 18=EFUSE_OUT_OF_RESET; 19=QUAD_DEC0_1_2; 20=BLE_FRONTEND; 21=PROG_AHB_TRIG_TIMEOUT; 22=SXPLL_NEED_RESET; 23=LP_CLK_CAL_DONE; 24=BROWNOUT_DETECTED
  [4:0] MUX_16 — IRQ_16 Source Selection
    0=SECURITY; 1=UART0 RX; 2=UART0 TX; 3=UART1 RX; 4=UART1 TX; 5=SPI0 RX; 6=SPI0 TX; 7=SPI1 RX; 8=SPI1 TX; 9=I2C0 RX; 10=I2C0 TX; 11=I2C1 RX; 12=I2C1 TX; 13=WDT0; 14=WDT1; 15=DUALTIMER0; 16=PROV_DMA_CTRL0; 17=SECURITY; 18=EFUSE_OUT_OF_RESET; 19=QUAD_DEC0_1_2; 20=BLE_FRONTEND; 21=PROG_AHB_TRIG_TIMEOUT; 22=SXPLL_NEED_RESET; 23=LP_CLK_CAL_DONE; 24=BROWNOUT_DETECTED
0xD4 IRQ_MUX_IO_SEL_5 8-bit — Arm Cortex IRQ Mux Selection (Refer to Interrupts Spreadsheet)
  [4:0] MUX_20 — IRQ_20 Source Selection
    0=BROWNOUT_DETECTED; 1=UART0 RX; 2=UART0 TX; 3=UART1 RX; 4=UART1 TX; 5=SPI0 RX; 6=SPI0 TX; 7=SPI1 RX; 8=SPI1 TX; 9=I2C0 RX; 10=I2C0 TX; 11=I2C1 RX; 12=I2C1 TX; 13=WDT0; 14=WDT1; 15=DUALTIMER0; 16=PROV_DMA_CTRL0; 17=SECURITY; 18=EFUSE_OUT_OF_RESET; 19=QUAD_DEC0_1_2; 20=BLE_FRONTEND; 21=PROG_AHB_TRIG_TIMEOUT; 22=SXPLL_NEED_RESET; 23=LP_CLK_CAL_DONE; 24=BROWNOUT_DETECTED
{0x15C+4i} PWM_{i}_CONTROL (i=1..4)
  [22:21] CLOCK_SEL — PWM Source Clock Frequency Select
    0=26MHz; 1=13MHz; 2=6.5MHz; 3=3.25MHz
  [18:9] AGCDATA_IN — agc value from AGC
  [8:5] PWM_PERIOD — programmable PWM update period
  [3] SAMPLE_METHOD
    0=Samples agcdata at >= 1024 cycles and does not lose precision; 1=Samples at PWM period but will lose LSBs if less than 1024
  [2] AGCDATA_FMT — AGC data format
  [1] OUTPUT_POLARITY — 1 to inverse the polarity
  [0] PWM_EN — Active High PWM Enable
0x170 MBIST_DUAL_STATUS ro — Reflects the status of MBIST from lpmcu and btmcu
  [20:0] MBIST_BUS — Observation of lpmcu and btmcu MBIST results
0x188 DUALTIMER_CTRL 8-bit — Dual Timer Control
  [1] CNTR_2_ENABLE — Enable Dual Timer 2 Decoder
  [0] CNTR_1_ENABLE — Enable Dual Timer 1 Decoder
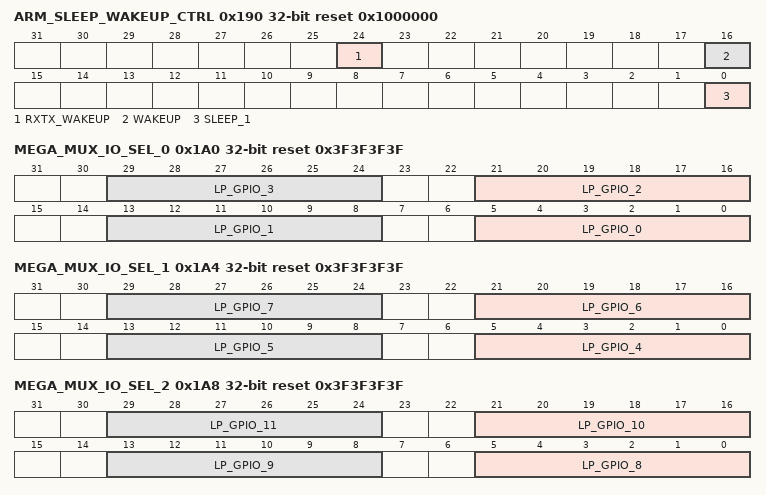
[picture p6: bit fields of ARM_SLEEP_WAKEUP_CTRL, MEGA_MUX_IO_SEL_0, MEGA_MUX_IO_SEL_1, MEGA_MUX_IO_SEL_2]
0x190 ARM_SLEEP_WAKEUP_CTRL reset 0x1000000 — Sleep and Wakeup Control for the AON Power Sequencer
  [24] RXTX_WAKEUP — Wakeup Request from the ARM to the RxTx Sequencer
  [16] WAKEUP — Wakeup Request from the ARM to the AON Power Sequencer
  [0] SLEEP_1 — Sleep Request 1 from the ARM to the AON Power Sequencer
0x1A0 MEGA_MUX_IO_SEL_0 reset 0x3F3F3F3F — Mega Mux Selection (Refer to Mega_Mux_IO Spreadsheet)
  [all] fields
    0=UART0_RXD; 1=UART0_TXD; 2=UART0_CTS; 3=UART0_RTS; 4=UART1_RXD; 5=UART1_TXD; 6=UART1_CTS; 7=UART1_RTS; 8=I2C0_SDA; 9=I2C0_SCL; 10=I2C1_SDA; 11=I2C1_SCL; {v}=PWM{v-12}_OUT (v=12..15); 16=32KHZ_CLK; 17=COEX_WLAN_TX; 18=COEX_WLAN_RX; 19=COEX_BLE_TX; 20=COEX_BLE_RX; 21=COEX_BLE_IN_PROCESS; 22=COEX_BLE_MBSY; 23=COEX_BLE_SYNC; 24=COEX_BLE_RXNTX; {v}=COEX_BLE_PTI_{v-25} (v=25..28); 29=QUAD_DEC0_A; 30=QUAD_DEC0_B; 31=QUAD_DEC1_A; 32=QUAD_DEC1_B; 33=QUAD_DEC2_A; 34=QUAD_DEC2_B
  [8n+5:8n] LP_GPIO_{n} (n=0..3) — LP_GPIO_{n} mega mux selection
0x1A4 MEGA_MUX_IO_SEL_1 reset 0x3F3F3F3F — Mega Mux Selection (Refer to Mega_Mux_IO Spreadsheet)
  [all] fields
    values as the fields of MEGA_MUX_IO_SEL_0
  [8n-27:8n-32] LP_GPIO_{n} (n=4..7) — LP_GPIO_{n} mega mux selection
0x1A8 MEGA_MUX_IO_SEL_2 reset 0x3F3F3F3F — Mega Mux Selection (Refer to Mega_Mux_IO Spreadsheet)
  [all] fields
    values as the fields of MEGA_MUX_IO_SEL_0
  [8n-59:8n-64] LP_GPIO_{n} (n=8..11) — LP_GPIO_{n} mega mux selection
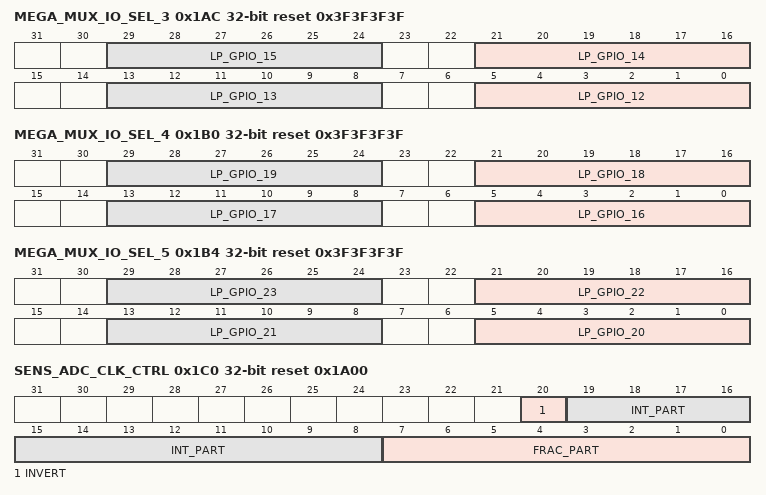
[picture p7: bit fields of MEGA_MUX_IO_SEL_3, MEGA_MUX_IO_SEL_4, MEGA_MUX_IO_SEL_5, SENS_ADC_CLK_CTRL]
0x1AC MEGA_MUX_IO_SEL_3 reset 0x3F3F3F3F — Mega Mux Selection (Refer to Mega_Mux_IO Spreadsheet)
  [all] fields
    values as the fields of MEGA_MUX_IO_SEL_0
  [8n-91:8n-96] LP_GPIO_{n} (n=12..15) — LP_GPIO_{n} mega mux selection
0x1B0 MEGA_MUX_IO_SEL_4 reset 0x3F3F3F3F — Mega Mux Selection (Refer to Mega_Mux_IO Spreadsheet)
  [all] fields
    values as the fields of MEGA_MUX_IO_SEL_0
  [8n-123:8n-128] LP_GPIO_{n} (n=16..19) — LP_GPIO_{n} mega mux selection
0x1B4 MEGA_MUX_IO_SEL_5 reset 0x3F3F3F3F — Mega Mux Selection (Refer to Mega_Mux_IO Spreadsheet)
  [all] fields
    values as the fields of MEGA_MUX_IO_SEL_0
  [8n-155:8n-160] LP_GPIO_{n} (n=20..23) — LP_GPIO_{n} mega mux selection
0x1B8 MEGA_MUX_IO_SEL_6 8-bit reset 0x3F — Mega Mux Selection (Refer to Mega_Mux_IO Spreadsheet)
  [5:0] LP_GPIO_24 — LP_GPIO_24 mega mux selection
    values as the fields of MEGA_MUX_IO_SEL_0
0x1C0 SENS_ADC_CLK_CTRL reset 0x1A00 — Clock control for the Sensor ADC
  [20] INVERT — Invert Sens ADC Clock
  [19:8] INT_PART — Integer part for the clock divider
  [7:0] FRAC_PART — Fractional part for the clock divider
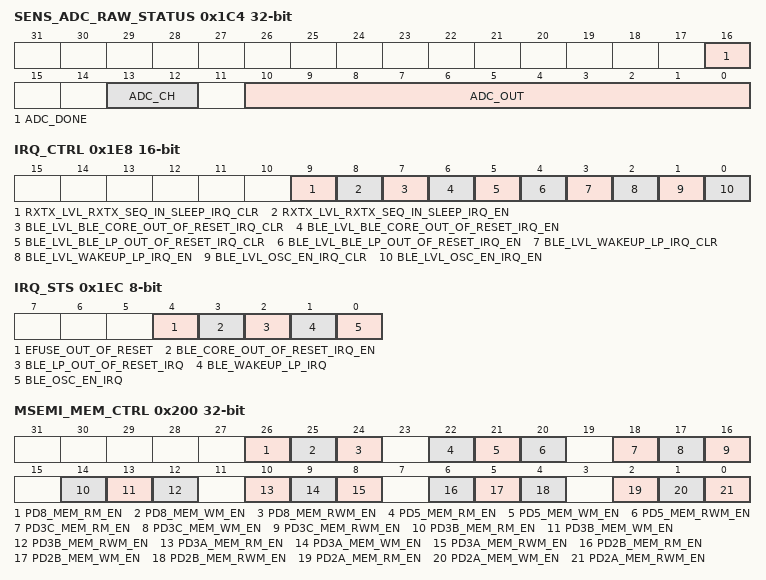
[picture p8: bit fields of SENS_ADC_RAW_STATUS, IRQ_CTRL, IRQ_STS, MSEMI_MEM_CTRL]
0x1C4 SENS_ADC_RAW_STATUS ro — Raw Status from the Sensor ADC
  [16] ADC_DONE — Raw Status of the sens_adc_done port of the PMU
  [13:12] ADC_CH — Raw Status of the sens_adc_ch port of the PMU
  [10:0] ADC_OUT — Raw Status of the sens_adc_out port of the PMU
{0x1C8+4i} SENS_ADC_CH{i}_DATA 16-bit ro (reset mask 0x7FF) (i=0..3) — Current data of the Sensor ADC for Channel {i}
0x1E8 IRQ_CTRL 16-bit — Configure the IRQ inputs to the system as either Rising Edge or Level Shift
  [9] RXTX_LVL_RXTX_SEQ_IN_SLEEP_IRQ_CLR — if rxtx_seq_in_sleep is enabled, setting irq clr to 1 will clear the irq request
  [8] RXTX_LVL_RXTX_SEQ_IN_SLEEP_IRQ_EN — Enable the rxtx_seq_in_sleep signal for Level Shift and Clear Mode
  [7] BLE_LVL_BLE_CORE_OUT_OF_RESET_IRQ_CLR — if core_out_of_reset is enabled, setting irq clr to 1 will clear the irq request
  [6] BLE_LVL_BLE_CORE_OUT_OF_RESET_IRQ_EN — Enable the core_out_of_reset signal for Level Shift and Clear Mode
  [5] BLE_LVL_BLE_LP_OUT_OF_RESET_IRQ_CLR — if lp_out_of_reset is enabled, setting irq clr to 1 will clear the irq request
  [4] BLE_LVL_BLE_LP_OUT_OF_RESET_IRQ_EN — Enable the lp_out_of_reset signal for Level Shift and Clear Mode
  [3] BLE_LVL_WAKEUP_LP_IRQ_CLR — if ble_lvl_wakeup_lp_irq_en is enabled, setting irq clr to 1 will clear the irq request
  [2] BLE_LVL_WAKEUP_LP_IRQ_EN — Enable the wakeup_lp signal for Level Shift and Clear Mode
  [1] BLE_LVL_OSC_EN_IRQ_CLR — if ble_lvl_osc_en_irq_en is enabled, setting irq clr to 1 will clear the irq request
  [0] BLE_LVL_OSC_EN_IRQ_EN — Enable the OSC_en signal for Level Shift and Clear Mode
0x1EC IRQ_STS 8-bit ro — Read the raw (no level or rise detect) IRQ inputs to the system from the designated cores
  [4] EFUSE_OUT_OF_RESET — Read the efuse_out_of_reset signal from the efuse wrapper
  [3] BLE_CORE_OUT_OF_RESET_IRQ_EN — Read the ble_core_out_of_reset_irq signal from the ble core
  [2] BLE_LP_OUT_OF_RESET_IRQ — Read the ble_lp_out_of_reset signal from the ble lp core
  [1] BLE_WAKEUP_LP_IRQ — Read the wakeup_lp_irq signal from the lp core
  [0] BLE_OSC_EN_IRQ — Read the OSC_en signal from the lp core
0x200 MSEMI_MEM_CTRL — Control the rwm, rm and wm on the Mobile Semi Memories
  [26] PD8_MEM_RM_EN — RM control for pd8 memory
  [25] PD8_MEM_WM_EN — WM control for pd8 memory
  [24] PD8_MEM_RWM_EN — RWM control for pd8 memory
  [22] PD5_MEM_RM_EN — RM control for pd5 memory
  [21] PD5_MEM_WM_EN — WM control for pd5 memory
  [20] PD5_MEM_RWM_EN — RWM control for pd5 memory
  [18] PD3C_MEM_RM_EN — RM control for pd3c memory
  [17] PD3C_MEM_WM_EN — WM control for pd3c memory
  [16] PD3C_MEM_RWM_EN — RWM control for pd3c memory
  [14] PD3B_MEM_RM_EN — RM control for pd3b memory
  [13] PD3B_MEM_WM_EN — WM control for pd3b memory
  [12] PD3B_MEM_RWM_EN — RWM control for pd3b memory
  [10] PD3A_MEM_RM_EN — RM control for pd3a memory
  [9] PD3A_MEM_WM_EN — WM control for pd3a memory
  [8] PD3A_MEM_RWM_EN — RWM control for pd3a memory
  [6] PD2B_MEM_RM_EN — RM control for pd2b memory
  [5] PD2B_MEM_WM_EN — WM control for pd2b memory
  [4] PD2B_MEM_RWM_EN — RWM control for pd2b memory
  [2] PD2A_MEM_RM_EN — RM control for pd2a memory
  [1] PD2A_MEM_WM_EN — WM control for pd2a memory
  [0] PD2A_MEM_RWM_EN — RWM control for pd2a memory
0x204 EFUSE_1_STATUS_3 — EFUSE_1_3 Status
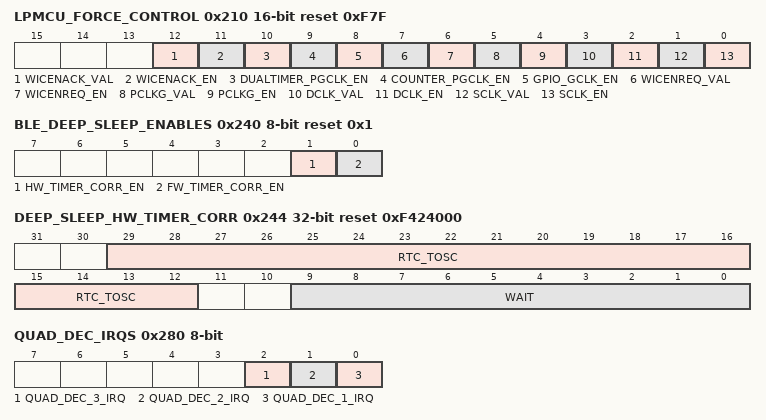
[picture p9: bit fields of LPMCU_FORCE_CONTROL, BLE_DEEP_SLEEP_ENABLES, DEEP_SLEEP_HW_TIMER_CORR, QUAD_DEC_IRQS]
0x210 LPMCU_FORCE_CONTROL 16-bit reset 0xF7F — Miscellaneous Force control values for LPMCU
  [12] WICENACK_VAL — Enable Force Control of WIC Enable Value - Requires Handshake from WIC when its ok to sleep
  [11] WICENACK_EN — Enable Force Control of WIC ACK to use WIC during Sleep Conditions - Requires Handshake from WIC when its ok to sleep
  [10] DUALTIMER_PGCLK_EN — Enable Force Control of DualTimer Modules PGClk (override clock gating and enable)
  [9] COUNTER_PGCLK_EN — Enable Force Control of Counter Modules Clk (override clock gating and enable)
  [8] GPIO_GCLK_EN — Enable Force Control of GPIO Modules Clk (override clock gating and enable)
  [7] WICENREQ_VAL — Enable Force Control of WIC Enable Value
  [6] WICENREQ_EN — Enable Force Control of WIC Enable Request to use WIC during Sleep Conditions
  [5] PCLKG_VAL — Enable Force Control of PCLKG Value
  [4] PCLKG_EN — Enable Force Control of PCLKG
  [3] DCLK_VAL — Enable Force Control of DCLK Value
  [2] DCLK_EN — Enable Force Control of DCLK
  [1] SCLK_VAL — Enable Force Control of SCLK Value
  [0] SCLK_EN — Enable Force Control of SCLK
0x214 ARM_IRQ_STATUS_0 ro — ARM Cortex M0 IRQ Status
0x218 ARM_IRQ_STATUS_1 ro — ARM Cortex M0 IRQ Status
0x240 BLE_DEEP_SLEEP_ENABLES 8-bit reset 0x1
  [1] HW_TIMER_CORR_EN — Enables HW Timer Correction Operation
  [0] FW_TIMER_CORR_EN — Enables FW Timer Correction Operation
0x244 DEEP_SLEEP_HW_TIMER_CORR reset 0xF424000 — Configures the HW auto correction algorithm of the fine/base timers after wakeup from deep sleep
  [29:12] RTC_TOSC — Period of RTC clock in us [7.11]
  [9:0] WAIT — Wait time in us after wakeup before correction begins
0x254 REMAP_IDRAM1_BASE_ADDR reset 0x8000 — ARM Cortex M0 idram 1 remap base addr
0x258 REMAP_IDRAM1_END_ADDR reset 0x1FFFF — ARM Cortex M0 idram 1 remap end addr
0x25C REMAP_IDRAM2_BASE_ADDR — ARM Cortex M0 idram 2 remap base addr
0x260 REMAP_IDRAM2_END_ADDR reset 0x7FFF — ARM Cortex M0 idram 2 remap end addr
0x264 REMAP_BOOT_BASE_ADDR reset 0x10000000 — ARM Cortex M0 bootrom remap base addr
0x268 REMAP_BOOT_END_ADDR reset 0x1001FFFF — ARM Cortex M0 bootrom remap end addr
0x280 QUAD_DEC_IRQS 8-bit ro — Reflects the IRQ status of the Quad Decoders
  [2] QUAD_DEC_3_IRQ — QUAD_DEC2 Interrupt
  [1] QUAD_DEC_2_IRQ — QUAD_DEC1 Interrupt
  [0] QUAD_DEC_1_IRQ — QUAD_DEC0 Interrupt
{0x280+4i} QUAD_DEC_{i}_STATUS 16-bit ro (i=1..3) — Current status of Quad Decoder {i}
  [15:0] COUNT — Current count of QUAD_DEC{i-1}
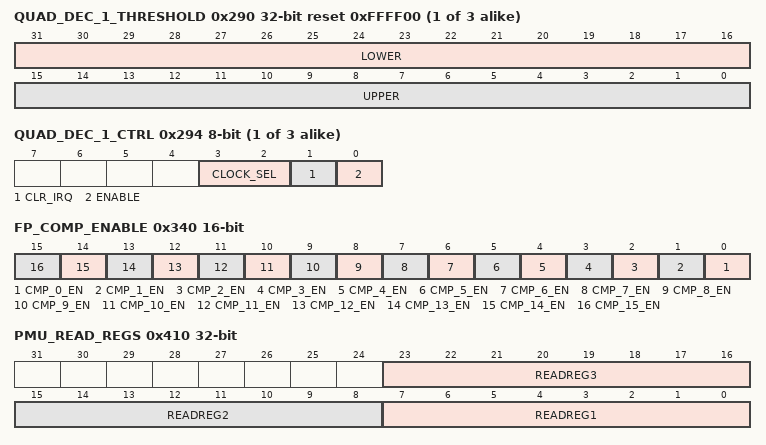
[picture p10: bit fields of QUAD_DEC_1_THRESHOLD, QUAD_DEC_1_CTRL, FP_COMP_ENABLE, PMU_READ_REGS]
{0x280+0x10*i} QUAD_DEC_{i}_THRESHOLD reset 0xFFFF00 (i=1..3) — Thresholds for Quad Decoder {i}
  [31:16] LOWER — Lower Threshold of counter for QUAD_DEC{i-1}
  [15:0] UPPER — Upper Threshold of counter for QUAD_DEC{i-1}
{0x284+0x10*i} QUAD_DEC_{i}_CTRL 8-bit (i=1..3) — Control for Quad Decoder {i}
  [3:2] CLOCK_SEL — Quad Decoder Source Clock Frequency Select
    0=26MHz; 1=13MHz; 2=6.5MHz; 3=3.25MHz
  [1] CLR_IRQ — Clear IRQ From Quad Decoder
  [0] ENABLE — Enable Quad Decoder
{0x2C0+4i} FP_COMP{i}_COMP (reset mask 0x1FFFF) (i=0..15) — Flash Breakpoint Compare Register {i}
{0x300+4i} FP_COMP{i}_REPLACE (reset mask 0x7FFFF) (i=0..14) — Flash Breakpoint Replace Register {i}
0x33C FP_COMP15_REPLACE (reset mask 0x7FFFF) — Flash Breakpoint Replace Register 14
0x340 FP_COMP_ENABLE 16-bit — Flash Breakpoint Enable Register
  [n] CMP_{n}_EN (n=0..15) — Enable Compare {n}
0x410 PMU_READ_REGS ro — PMU Status Registers
  [23:16] READREG3 — PMU Read Register 3
  [15:8] READREG2 — PMU Read Register 2
  [7:0] READREG1 — PMU Read Register 1
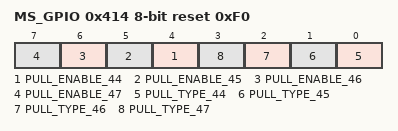
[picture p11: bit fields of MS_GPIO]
0x414 MS_GPIO 8-bit reset 0xF0 — Control for Mixed Signal GPIOs
  [n-40] PULL_ENABLE_{n} (n=44..47) — Active Low Pull Enable for Mixed Signal LP_GPIO_{n}
  [n-44] PULL_TYPE_{n} (n=44..47) — Mixed Signal LP_GPIO_{n} Pull Type Select. 1: PD, 0: PU.
0x420 AON_SLEEP_TIMER_COUNTER ro — Current value of the AON Sleep Timer (syncd to ARM clock)
